# HDSC_HC32F480 register map
Vendor: HDSC Co.Ltd; Series: ARMCM4; File version: 1.2
CPU: CM0 r0p0, little endian, no MPU, no FPU, 3 interrupt priority bits
Registers are 16-bit, read-write, reset 0x0 unless marked. A register's access mark holds for its fields unless they carry their own. Offsets are from the block's base; [hi:lo] are bit positions; {n}, {i} and the like mark numbered series.

## SDIOC
Base 0x40010C00
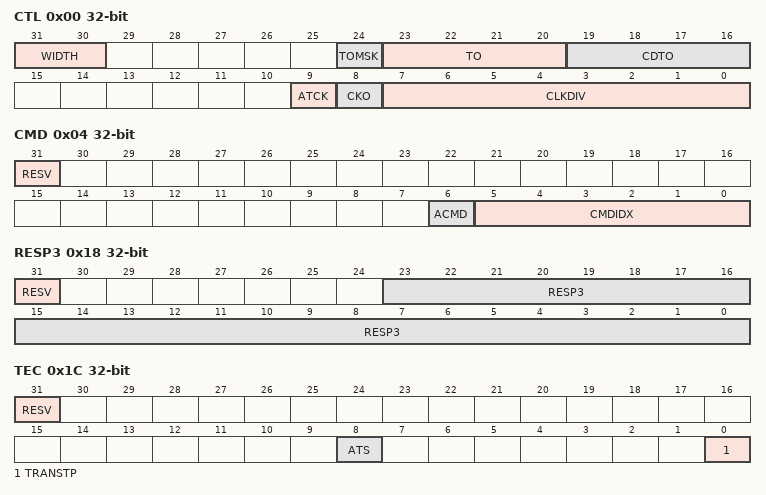
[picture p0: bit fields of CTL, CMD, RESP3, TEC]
0x00 CTL 32-bit
  [31:30] WIDTH, [24] TOMSK, [23:20] TO, [19:16] CDTO, [9] ATCK, [8] CKO, [7:0] CLKDIV
0x04 CMD 32-bit
  [31] RESV, [6] ACMD, [5:0] CMDIDX
0x08 ARG 32-bit
{0xC+4i} RESP{i} 32-bit ro (i=0..2)
0x18 RESP3 32-bit ro
  [31] RESV rw, [23:0] RESP3
0x1C TEC 32-bit
  [31] RESV, [8] ATS, [0] TRANSTP
0x20 BLKCNT 32-bit
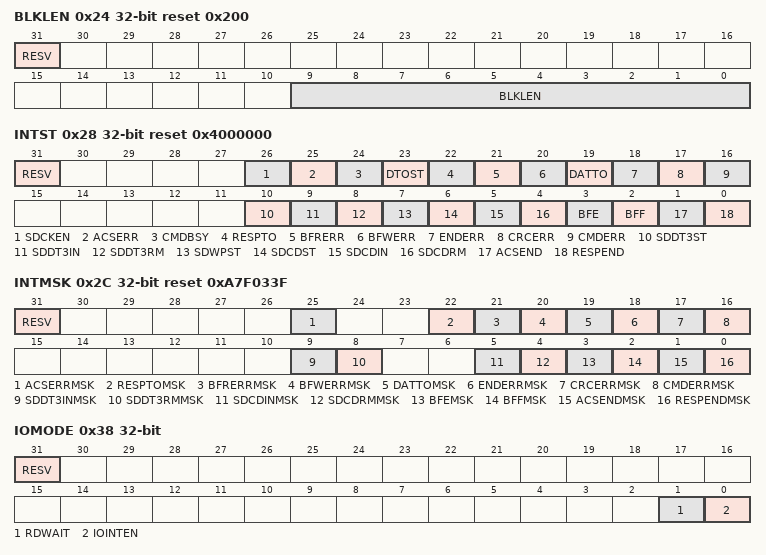
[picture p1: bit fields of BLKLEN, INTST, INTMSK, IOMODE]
0x24 BLKLEN 32-bit reset 0x200
  [31] RESV, [9:0] BLKLEN
0x28 INTST 32-bit reset 0x4000000
  [31] RESV, [26] SDCKEN ro, [25] ACSERR, [24] CMDBSY, [23] DTOST ro, [22] RESPTO, [21] BFRERR, [20] BFWERR, [19] DATTO, [18] ENDERR, [17] CRCERR, [16] CMDERR, [10] SDDT3ST ro, [9] SDDT3IN, [8] SDDT3RM, [7] SDWPST ro, [6] SDCDST ro, [5] SDCDIN, [4] SDCDRM, [3] BFE, [2] BFF, [1] ACSEND, [0] RESPEND
0x2C INTMSK 32-bit reset 0xA7F033F
  [31] RESV, [25] ACSERRMSK, [22] RESPTOMSK, [21] BFRERRMSK, [20] BFWERRMSK, [19] DATTOMSK, [18] ENDERRMSK, [17] CRCERRMSK, [16] CMDERRMSK, [9] SDDT3INMSK, [8] SDDT3RMMSK, [5] SDCDINMSK, [4] SDCDRMMSK, [3] BFEMSK, [2] BFFMSK, [1] ACSENDMSK, [0] RESPENDMSK
0x34 BUFFER 32-bit
0x38 IOMODE 32-bit
  [31] RESV, [1] RDWAIT, [0] IOINTEN
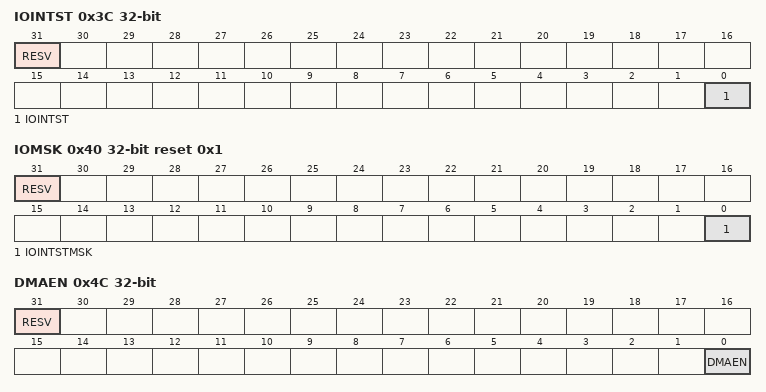
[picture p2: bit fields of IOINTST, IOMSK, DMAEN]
0x3C IOINTST 32-bit
  [31] RESV, [0] IOINTST
0x40 IOMSK 32-bit reset 0x1
  [31] RESV, [0] IOINTSTMSK
0x4C DMAEN 32-bit
  [31] RESV, [0] DMAEN

## SMI
Base 0x40055000
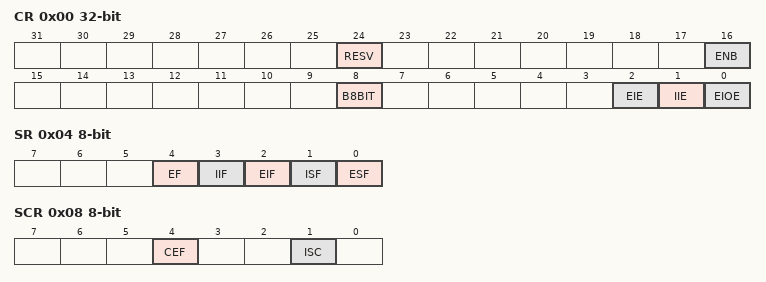
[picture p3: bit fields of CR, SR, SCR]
0x00 CR 32-bit
  [24] RESV, [16] ENB, [8] B8BIT, [2] EIE, [1] IIE, [0] EIOE
0x04 SR 8-bit ro
  [4] EF, [3] IIF, [2] EIF, [1] ISF, [0] ESF
0x08 SCR 8-bit
  [4] CEF, [1] ISC

## SPI
Base 0x4001C000
0x00 DR 32-bit
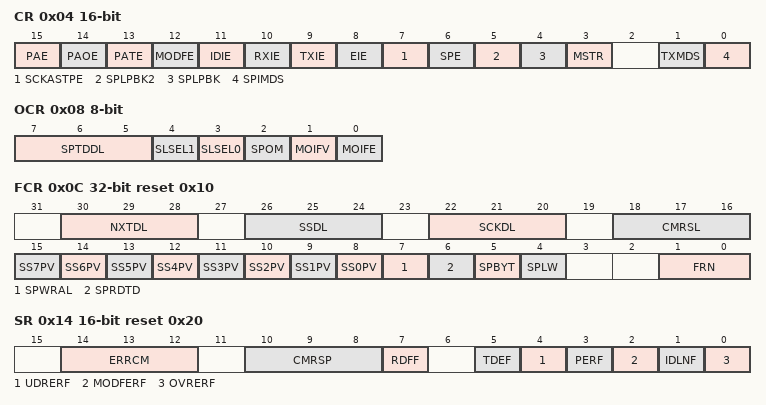
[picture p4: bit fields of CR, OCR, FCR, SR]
0x04 CR
  [15] PAE, [14] PAOE, [13] PATE, [12] MODFE, [11] IDIE, [10] RXIE, [9] TXIE, [8] EIE, [7] SCKASTPE, [6] SPE, [5] SPLPBK2, [4] SPLPBK, [3] MSTR, [1] TXMDS, [0] SPIMDS
0x08 OCR 8-bit
  [7:5] SPTDDL, [4] SLSEL1, [3] SLSEL0, [2] SPOM, [1] MOIFV, [0] MOIFE
0x0C FCR 32-bit reset 0x10
  [30:28] NXTDL, [26:24] SSDL, [22:20] SCKDL, [18:16] CMRSL, [n+8] SS{n}PV (n=0..7), [7] SPWRAL, [6] SPRDTD, [5] SPBYT, [4] SPLW, [1:0] FRN
0x10 BRR 8-bit reset 0xFF
0x14 SR reset 0x20
  [14:12] ERRCM, [10:8] CMRSP, [7] RDFF, [5] TDEF, [4] UDRERF, [3] PERF, [2] MODFERF, [1] IDLNF, [0] OVRERF
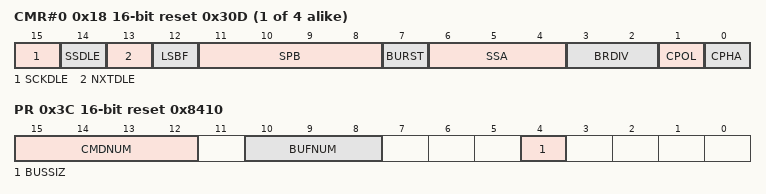
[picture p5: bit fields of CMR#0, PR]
{0x18+4i} CMR#{i} reset 0x30D (i=0..3)
  [15] SCKDLE, [14] SSDLE, [13] NXTDLE, [12] LSBF, [11:8] SPB, [7] BURST, [6:4] SSA, [3:2] BRDIV, [1] CPOL, [0] CPHA
0x38 DCR2
  [8] BYSW
0x3C PR reset 0x8410
  [15:12] CMDNUM, [10:8] BUFNUM, [4] BUSSIZ

## SRAMC
Base 0x40050800
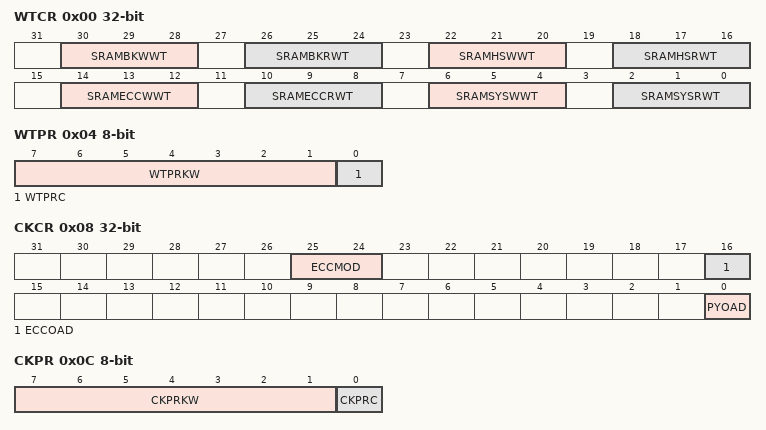
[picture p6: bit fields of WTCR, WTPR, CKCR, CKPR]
0x00 WTCR 32-bit
  [30:28] SRAMBKWWT, [26:24] SRAMBKRWT, [22:20] SRAMHSWWT, [18:16] SRAMHSRWT, [14:12] SRAMECCWWT, [10:8] SRAMECCRWT, [6:4] SRAMSYSWWT, [2:0] SRAMSYSRWT
0x04 WTPR 8-bit
  [7:1] WTPRKW, [0] WTPRC
0x08 CKCR 32-bit
  [25:24] ECCMOD, [16] ECCOAD, [0] PYOAD
0x0C CKPR 8-bit
  [7:1] CKPRKW, [0] CKPRC
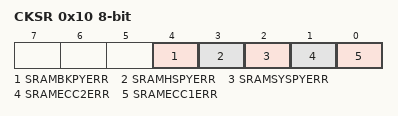
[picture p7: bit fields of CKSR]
0x10 CKSR 8-bit
  [4] SRAMBKPYERR, [3] SRAMHSPYERR, [2] SRAMSYSPYERR, [1] SRAMECC2ERR, [0] SRAMECC1ERR

## SWDT
Base 0x40049400
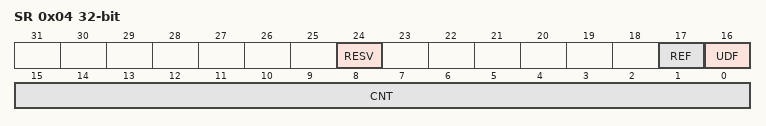
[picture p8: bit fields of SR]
0x04 SR 32-bit ro
  [24] RESV rw, [17] REF rw, [16] UDF rw, [15:0] CNT
0x08 RR ro

## SYSREG
Base 0x40054000
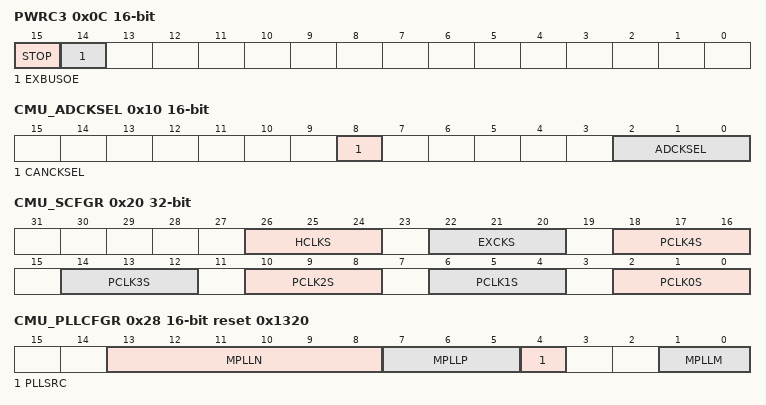
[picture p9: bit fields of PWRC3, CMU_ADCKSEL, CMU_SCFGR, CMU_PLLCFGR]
0x0C PWRC3
  [15] STOP, [14] EXBUSOE
0x10 CMU_ADCKSEL
  [8] CANCKSEL, [2:0] ADCKSEL
0x20 CMU_SCFGR 32-bit
  [26:24] HCLKS, [22:20] EXCKS, [4n+2:4n] PCLK{n}S (n=0..4)
0x24 CMU_UFSCKCFGR 8-bit reset 0x40
  [7:4] USBCKS
0x26 CMU_CKSWR 8-bit reset 0x1
  [2:0] CKSW
0x28 CMU_PLLCFGR reset 0x1320
  [13:8] MPLLN, [7:5] MPLLP, [4] PLLSRC, [1:0] MPLLM
0x2A CMU_PLLCR 8-bit reset 0x1
  [0] MPLLOFF
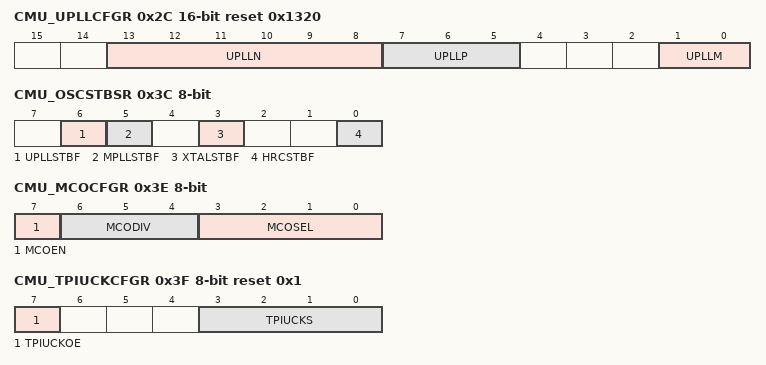
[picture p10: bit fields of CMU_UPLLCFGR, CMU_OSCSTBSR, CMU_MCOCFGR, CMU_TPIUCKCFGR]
0x2C CMU_UPLLCFGR reset 0x1320
  [13:8] UPLLN, [7:5] UPLLP, [1:0] UPLLM
0x2E CMU_UPLLCR 8-bit reset 0x1
  [0] UPLLOFF
0x32 CMU_XTALCR 8-bit reset 0x1
  [0] XTALSTP
0x36 CMU_HRCCR 8-bit
  [0] HRCSTP
0x38 CMU_MRCCR 8-bit
  [0] MRCSTP
0x3C CMU_OSCSTBSR 8-bit
  [6] UPLLSTBF, [5] MPLLSTBF, [3] XTALSTBF, [0] HRCSTBF
0x3E CMU_MCOCFGR 8-bit
  [7] MCOEN, [6:4] MCODIV, [3:0] MCOSEL
0x3F CMU_TPIUCKCFGR 8-bit reset 0x1
  [7] TPIUCKOE, [3:0] TPIUCKS
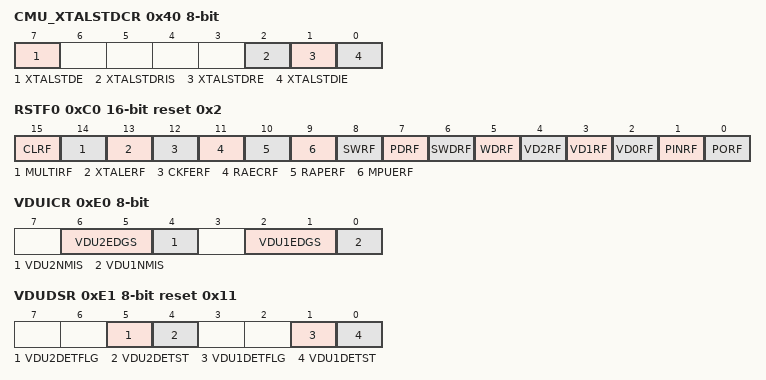
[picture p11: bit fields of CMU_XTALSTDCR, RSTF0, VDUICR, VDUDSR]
0x40 CMU_XTALSTDCR 8-bit
  [7] XTALSTDE, [2] XTALSTDRIS, [1] XTALSTDRE, [0] XTALSTDIE
0x41 CMU_XTALSTDSR 8-bit
  [0] XTALSTDF
0x61 CMU_MRCTRM 8-bit
0x62 CMU_HRCTRM 8-bit
0xA2 CMU_XTALSTBCR 8-bit reset 0x5
  [3:0] XTALSTB
0xC0 RSTF0 reset 0x2
  [15] CLRF, [14] MULTIRF, [13] XTALERF, [12] CKFERF, [11] RAECRF, [10] RAPERF, [9] MPUERF, [8] SWRF, [7] PDRF, [6] SWDRF, [5] WDRF, [4] VD2RF, [3] VD1RF, [2] VD0RF, [1] PINRF, [0] PORF
0xE0 VDUICR 8-bit
  [6:5] VDU2EDGS, [4] VDU2NMIS, [2:1] VDU1EDGS, [0] VDU1NMIS
0xE1 VDUDSR 8-bit reset 0x11
  [5] VDU2DETFLG, [4] VDU2DETST, [1] VDU1DETFLG, [0] VDU1DETST
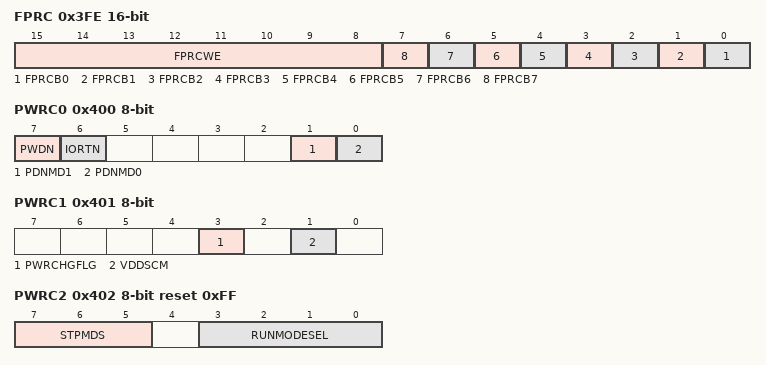
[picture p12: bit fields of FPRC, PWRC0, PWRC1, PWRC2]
0x3FE FPRC
  [15:8] FPRCWE, [n] FPRCB{n} (n=0..7)
0x400 PWRC0 8-bit
  [7] PWDN, [6] IORTN, [1] PDNMD1, [0] PDNMD0
0x401 PWRC1 8-bit
  [3] PWRCHGFLG, [1] VDDSCM
0x402 PWRC2 8-bit reset 0xFF
  [7:5] STPMDS, [3:0] RUNMODESEL
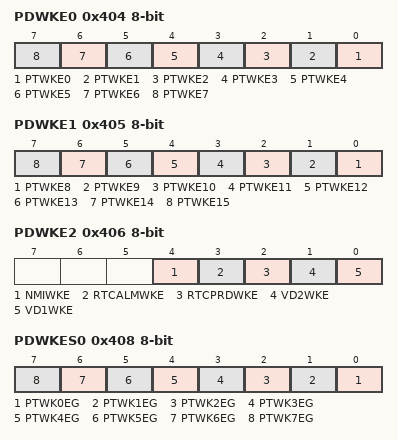
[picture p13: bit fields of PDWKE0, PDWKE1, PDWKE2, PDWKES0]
0x404 PDWKE0 8-bit
  [n] PTWKE{n} (n=0..7)
0x405 PDWKE1 8-bit
  [n-8] PTWKE{n} (n=8..15)
0x406 PDWKE2 8-bit
  [4] NMIWKE, [3] RTCALMWKE, [2] RTCPRDWKE, [1] VD2WKE, [0] VD1WKE
0x408 PDWKES0 8-bit
  [n] PTWK{n}EG (n=0..7)
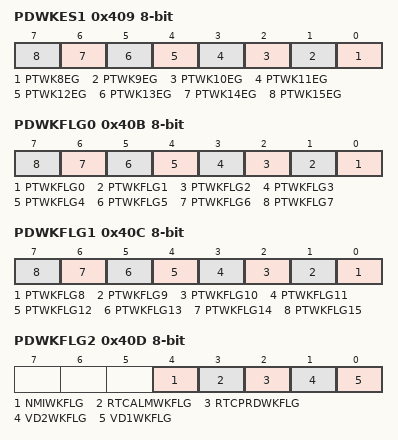
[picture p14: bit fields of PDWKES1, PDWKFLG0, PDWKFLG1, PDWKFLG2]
0x409 PDWKES1 8-bit
  [n-8] PTWK{n}EG (n=8..15)
0x40A PDWKES2 8-bit
  [4] NMIEG
0x40B PDWKFLG0 8-bit
  [n] PTWKFLG{n} (n=0..7)
0x40C PDWKFLG1 8-bit
  [n-8] PTWKFLG{n} (n=8..15)
0x40D PDWKFLG2 8-bit
  [4] NMIWKFLG, [3] RTCALMWKFLG, [2] RTCPRDWKFLG, [1] VD2WKFLG, [0] VD1WKFLG
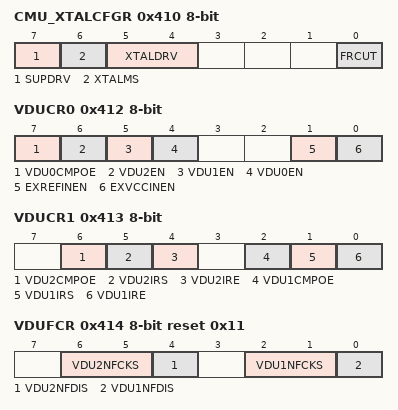
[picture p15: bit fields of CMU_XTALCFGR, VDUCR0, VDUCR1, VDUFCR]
0x410 CMU_XTALCFGR 8-bit
  [7] SUPDRV, [6] XTALMS, [5:4] XTALDRV, [0] FRCUT
0x412 VDUCR0 8-bit
  [7] VDU0CMPOE, [6] VDU2EN, [5] VDU1EN, [4] VDU0EN, [1] EXREFINEN, [0] EXVCCINEN
0x413 VDUCR1 8-bit
  [6] VDU2CMPOE, [5] VDU2IRS, [4] VDU2IRE, [2] VDU1CMPOE, [1] VDU1IRS, [0] VDU1IRE
0x414 VDUFCR 8-bit reset 0x11
  [6:5] VDU2NFCKS, [4] VDU2NFDIS, [2:1] VDU1NFCKS, [0] VDU1NFDIS
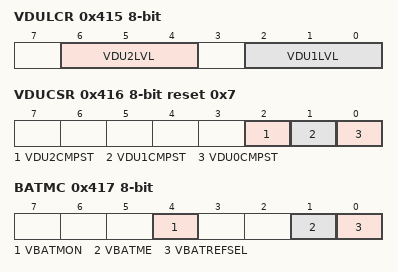
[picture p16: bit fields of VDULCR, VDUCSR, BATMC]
0x415 VDULCR 8-bit
  [6:4] VDU2LVL, [2:0] VDU1LVL
0x416 VDUCSR 8-bit reset 0x7
  [2] VDU2CMPST, [1] VDU1CMPST, [0] VDU0CMPST
0x417 BATMC 8-bit
  [4] VBATMON, [1] VBATME, [0] VBATREFSEL
